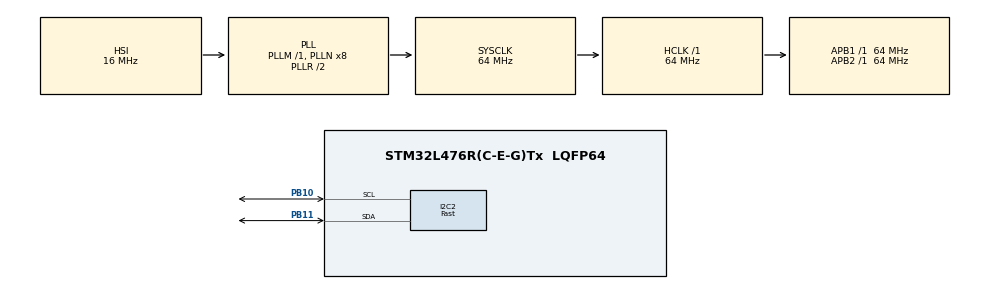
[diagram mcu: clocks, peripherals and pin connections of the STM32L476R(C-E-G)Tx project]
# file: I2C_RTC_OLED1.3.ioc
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I2C2.I2C_Speed_Mode=I2C_Fast
I2C2.Timing=0x00602173
Mcu.Family=STM32L4
Mcu.Name=STM32L476R(C-E-G)Tx
Mcu.Package=LQFP64
NVIC.PriorityGroup=NVIC_PRIORITYGROUP_4
PA13\ (JTMS-SWDIO).Mode=Serial_Wire
PA13\ (JTMS-SWDIO).Signal=SYS_JTMS-SWDIO
PA14\ (JTCK-SWCLK).Mode=Serial_Wire
PA14\ (JTCK-SWCLK).Signal=SYS_JTCK-SWCLK
PB10.Mode=I2C
PB10.Signal=I2C2_SCL
PB11.Mode=I2C
PB11.Signal=I2C2_SDA
ProjectManager.HeapSize=0x200
ProjectManager.StackSize=0x400
ProjectManager.TargetToolchain=STM32CubeIDE
RCC.ADCFreq_Value=64000000
RCC.AHBFreq_Value=64000000
RCC.APB1Freq_Value=64000000
RCC.APB1TimFreq_Value=64000000
RCC.APB2Freq_Value=64000000
RCC.APB2TimFreq_Value=64000000
RCC.CortexFreq_Value=64000000
RCC.HCLKFreq_Value=64000000
RCC.HSE_VALUE=8000000
RCC.HSI_VALUE=16000000
RCC.LSE_VALUE=32768
RCC.MSI_VALUE=4000000
RCC.PLLSourceVirtual=RCC_PLLSOURCE_HSI
RCC.SYSCLKFreq_VALUE=64000000
RCC.SYSCLKSource=RCC_SYSCLKSOURCE_PLLCLK
RCC.USBFreq_Value=64000000
RCC.VCOOutputFreq_Value=128000000
RTC.Date=10
RTC.Hours=11
RTC.Minutes=41
RTC.Month=RTC_MONTH_AUGUST
RTC.WeekDay=RTC_WEEKDAY_THURSDAY
RTC.Year=23
VP_RTC_VS_RTC_Activate.Mode=RTC_Enabled
VP_RTC_VS_RTC_Calendar.Mode=RTC_Calendar
board=custom

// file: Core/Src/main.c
/* USER CODE BEGIN Header */
/**
  ******************************************************************************
  * @file           : main.c
  * @brief          : Main program body
  ******************************************************************************
  * @attention
  *
  * Copyright (c) 2023 STMicroelectronics.
  * All rights reserved.
  *
  * This software is licensed under terms that can be found in the LICENSE file
  * in the root directory of this software component.
  * If no LICENSE file comes with this software, it is provided AS-IS.
  *
  ******************************************************************************
  */
/* USER CODE END Header */
#include "main.h"

/* USER CODE BEGIN Includes */
#include "fonts.h"
#include "ssd1306.h"
#include "string.h"
/* USER CODE END Includes */

I2C_HandleTypeDef hi2c2;

RTC_HandleTypeDef hrtc;

void SystemClock_Config(void);
static void MX_GPIO_Init(void);
static void MX_I2C2_Init(void);
static void MX_RTC_Init(void);

int main(void)
{
  /* USER CODE BEGIN 1 */
	RTC_TimeTypeDef sTime;
	RTC_DateTypeDef DateToUpdate;
  /* USER CODE END 1 */

  /* MCU Configuration--------------------------------------------------------*/

  /* Reset of all peripherals, Initializes the Flash interface and the Systick. */
  HAL_Init();

  /* Configure the system clock */
  SystemClock_Config();

  /* Initialize all configured peripherals */
  MX_GPIO_Init();
  MX_I2C2_Init();
  MX_RTC_Init();
  /* USER CODE BEGIN 2 */
    SSD1306_Init();
    char dateStr[12];
  	char timeStr[12];
    SSD1306_GotoXY (0,0);
    SSD1306_Puts ("YASEMIN", &Font_11x18, 1);
    SSD1306_GotoXY (0, 30);
    SSD1306_Puts ("CELIK", &Font_11x18, 1);
    SSD1306_UpdateScreen();
    HAL_Delay (1000);
    SSD1306_ScrollRight(0,7);
    HAL_Delay(3000);
    SSD1306_ScrollLeft(0,7);
    HAL_Delay(3000);
    SSD1306_Stopscroll();
    SSD1306_Clear();
  /* USER CODE END 2 */

  /* Infinite loop */
  while (1)
  {

    /* USER CODE BEGIN 3 */
	  	  	  	  	  	HAL_RTC_GetTime(&hrtc, &sTime, RTC_FORMAT_BIN);
	  	  	  	  	  	HAL_RTC_GetDate(&hrtc, &DateToUpdate, RTC_FORMAT_BIN);

	    	            sprintf(timeStr, "%02d:%02d:%02d", sTime.Hours, sTime.Minutes, sTime.Seconds);
	    	            sprintf(dateStr, "%02d-%02d-%02d", DateToUpdate.Date, DateToUpdate.Month,2000 + DateToUpdate.Year);
	    	            SSD1306_GotoXY(0, 0);
	    	            SSD1306_Puts("Saat:", &Font_7x10, 1);
	    	            SSD1306_GotoXY(40, 0);
	    	            SSD1306_Puts(timeStr, &Font_7x10, 1);
	    	            SSD1306_GotoXY(0, 20);
	    	            SSD1306_Puts("Tarih:", &Font_7x10, 1);
	    	            SSD1306_GotoXY(40, 20);
	    	            SSD1306_Puts(dateStr, &Font_7x10, 1);
	    	            SSD1306_UpdateScreen();
	    	            HAL_Delay(1000);
  }
  /* USER CODE END 3 */
}

void SystemClock_Config(void)
{
  RCC_OscInitTypeDef RCC_OscInitStruct = {0};
  RCC_ClkInitTypeDef RCC_ClkInitStruct = {0};

  /** Configure the main internal regulator output voltage
  */
  if (HAL_PWREx_ControlVoltageScaling(PWR_REGULATOR_VOLTAGE_SCALE1) != HAL_OK)
  {
    Error_Handler();
  }

  /** Initializes the RCC Oscillators according to the specified parameters
  * in the RCC_OscInitTypeDef structure.
  */
  RCC_OscInitStruct.OscillatorType = RCC_OSCILLATORTYPE_HSI|RCC_OSCILLATORTYPE_LSI;
  RCC_OscInitStruct.HSIState = RCC_HSI_ON;
  RCC_OscInitStruct.HSICalibrationValue = RCC_HSICALIBRATION_DEFAULT;
  RCC_OscInitStruct.LSIState = RCC_LSI_ON;
  RCC_OscInitStruct.PLL.PLLState = RCC_PLL_ON;
  RCC_OscInitStruct.PLL.PLLSource = RCC_PLLSOURCE_HSI;
  RCC_OscInitStruct.PLL.PLLM = 1;
  RCC_OscInitStruct.PLL.PLLN = 8;
  RCC_OscInitStruct.PLL.PLLP = RCC_PLLP_DIV7;
  RCC_OscInitStruct.PLL.PLLQ = RCC_PLLQ_DIV2;
  RCC_OscInitStruct.PLL.PLLR = RCC_PLLR_DIV2;
  if (HAL_RCC_OscConfig(&RCC_OscInitStruct) != HAL_OK)
  {
    Error_Handler();
  }

  /** Initializes the CPU, AHB and APB buses clocks
  */
  RCC_ClkInitStruct.ClockType = RCC_CLOCKTYPE_HCLK|RCC_CLOCKTYPE_SYSCLK
                              |RCC_CLOCKTYPE_PCLK1|RCC_CLOCKTYPE_PCLK2;
  RCC_ClkInitStruct.SYSCLKSource = RCC_SYSCLKSOURCE_PLLCLK;
  RCC_ClkInitStruct.AHBCLKDivider = RCC_SYSCLK_DIV1;
  RCC_ClkInitStruct.APB1CLKDivider = RCC_HCLK_DIV1;
  RCC_ClkInitStruct.APB2CLKDivider = RCC_HCLK_DIV1;

  if (HAL_RCC_ClockConfig(&RCC_ClkInitStruct, FLASH_LATENCY_3) != HAL_OK)
  {
    Error_Handler();
  }
}

static void MX_I2C2_Init(void)
{

  hi2c2.Instance = I2C2;
  hi2c2.Init.Timing = 0x00602173;
  hi2c2.Init.OwnAddress1 = 0;
  hi2c2.Init.AddressingMode = I2C_ADDRESSINGMODE_7BIT;
  hi2c2.Init.DualAddressMode = I2C_DUALADDRESS_DISABLE;
  hi2c2.Init.OwnAddress2 = 0;
  hi2c2.Init.OwnAddress2Masks = I2C_OA2_NOMASK;
  hi2c2.Init.GeneralCallMode = I2C_GENERALCALL_DISABLE;
  hi2c2.Init.NoStretchMode = I2C_NOSTRETCH_DISABLE;
  if (HAL_I2C_Init(&hi2c2) != HAL_OK)
  {
    Error_Handler();
  }

  /** Configure Analogue filter
  */
  if (HAL_I2CEx_ConfigAnalogFilter(&hi2c2, I2C_ANALOGFILTER_ENABLE) != HAL_OK)
  {
    Error_Handler();
  }

  /** Configure Digital filter
  */
  if (HAL_I2CEx_ConfigDigitalFilter(&hi2c2, 0) != HAL_OK)
  {
    Error_Handler();
  }

}

static void MX_RTC_Init(void)
{

  RTC_TimeTypeDef sTime = {0};
  RTC_DateTypeDef sDate = {0};

  /** Initialize RTC Only
  */
  hrtc.Instance = RTC;
  hrtc.Init.HourFormat = RTC_HOURFORMAT_24;
  hrtc.Init.AsynchPrediv = 127;
  hrtc.Init.SynchPrediv = 255;
  hrtc.Init.OutPut = RTC_OUTPUT_DISABLE;
  hrtc.Init.OutPutRemap = RTC_OUTPUT_REMAP_NONE;
  hrtc.Init.OutPutPolarity = RTC_OUTPUT_POLARITY_HIGH;
  hrtc.Init.OutPutType = RTC_OUTPUT_TYPE_OPENDRAIN;
  if (HAL_RTC_Init(&hrtc) != HAL_OK)
  {
    Error_Handler();
  }

  /** Initialize RTC and set the Time and Date
  */
  sTime.Hours = 0x11;
  sTime.Minutes = 0x41;
  sTime.Seconds = 0x0;
  sTime.DayLightSaving = RTC_DAYLIGHTSAVING_NONE;
  sTime.StoreOperation = RTC_STOREOPERATION_RESET;
  if (HAL_RTC_SetTime(&hrtc, &sTime, RTC_FORMAT_BCD) != HAL_OK)
  {
    Error_Handler();
  }
  sDate.WeekDay = RTC_WEEKDAY_THURSDAY;
  sDate.Month = RTC_MONTH_AUGUST;
  sDate.Date = 0x10;
  sDate.Year = 0x23;

  if (HAL_RTC_SetDate(&hrtc, &sDate, RTC_FORMAT_BCD) != HAL_OK)
  {
    Error_Handler();
  }

}

static void MX_GPIO_Init(void)
{

  /* GPIO Ports Clock Enable */
  __HAL_RCC_GPIOB_CLK_ENABLE();
  __HAL_RCC_GPIOA_CLK_ENABLE();

}

void Error_Handler(void)
{
  __disable_irq();
  while (1)
  {
  }
}
